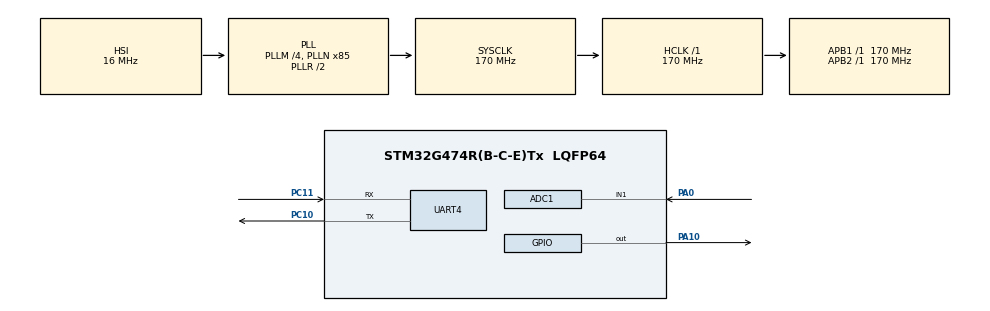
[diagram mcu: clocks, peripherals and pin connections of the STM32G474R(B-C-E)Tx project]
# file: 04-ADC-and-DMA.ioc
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ADC1.Channel-0\#ChannelRegularConversion=ADC_CHANNEL_1
ADC1.ClockPrescaler=ADC_CLOCK_ASYNC_DIV4
ADC1.ContinuousConvMode=ENABLE
ADC1.DMAContinuousRequests=ENABLE
ADC1.NbrOfConversionFlag=1
ADC1.OffsetNumber-0\#ChannelRegularConversion=ADC_OFFSET_NONE
ADC1.Rank-0\#ChannelRegularConversion=1
ADC1.SamplingTime-0\#ChannelRegularConversion=ADC_SAMPLETIME_2CYCLES_5
ADC1.master=1
Dma.ADC1.0.Direction=DMA_PERIPH_TO_MEMORY
Dma.ADC1.0.EventEnable=DISABLE
Dma.ADC1.0.Instance=DMA1_Channel1
Dma.ADC1.0.MemDataAlignment=DMA_MDATAALIGN_HALFWORD
Dma.ADC1.0.MemInc=DMA_MINC_ENABLE
Dma.ADC1.0.Mode=DMA_CIRCULAR
Dma.ADC1.0.PeriphDataAlignment=DMA_PDATAALIGN_HALFWORD
Dma.ADC1.0.PeriphInc=DMA_PINC_DISABLE
Dma.ADC1.0.Polarity=HAL_DMAMUX_REQ_GEN_RISING
Dma.ADC1.0.Priority=DMA_PRIORITY_LOW
Dma.ADC1.0.RequestNumber=1
Dma.ADC1.0.SignalID=NONE
Dma.ADC1.0.SyncEnable=DISABLE
Dma.ADC1.0.SyncPolarity=HAL_DMAMUX_SYNC_NO_EVENT
Dma.ADC1.0.SyncRequestNumber=1
Dma.ADC1.0.SyncSignalID=NONE
Dma.Request0=ADC1
Mcu.Family=STM32G4
Mcu.Name=STM32G474R(B-C-E)Tx
Mcu.Package=LQFP64
NUCLEO-G474RE.BUTTON=1
NUCLEO-G474RE.LD2=true
NUCLEO-G474RE.VCP=false
NVIC.DMA1_Channel1_IRQn=true\:0\:0\:false\:false\:true\:false\:true\:true
NVIC.EXTI15_10_IRQn=true\:0\:0\:false\:false\:true\:false\:true\:true
NVIC.PriorityGroup=NVIC_PRIORITYGROUP_4
PA0.Mode=IN1-Single-Ended
PA0.Signal=ADC1_IN1
PA10.Signal=GPIO_Output
PA13.GPIO_Label=T_SWDIO
PA13.Signal=SYS_JTMS-SWDIO
PA14.GPIO_Label=T_SWCLK
PA14.Signal=SYS_JTCK-SWCLK
PB3.GPIO_Label=T_SWO
PB3.Signal=SYS_JTDO-SWO
PC10.Mode=Asynchronous
PC10.Signal=UART4_TX
PC11.Mode=Asynchronous
PC11.Signal=UART4_RX
PC14-OSC32_IN.GPIO_Label=RCC_OSC32_IN
PC14-OSC32_IN.Signal=RCC_OSC32_IN
PC15-OSC32_OUT.GPIO_Label=RCC_OSC32_OUT
PC15-OSC32_OUT.Signal=RCC_OSC32_OUT
PF0-OSC_IN.GPIO_Label=RCC_OSC_IN
PF0-OSC_IN.Signal=RCC_OSC_IN
PF1-OSC_OUT.GPIO_Label=RCC_OSC_OUT
PF1-OSC_OUT.Signal=RCC_OSC_OUT
ProjectManager.HeapSize=0x200
ProjectManager.StackSize=0x400
ProjectManager.TargetToolchain=STM32CubeIDE
RCC.ADC12Freq_Value=170000000
RCC.ADC345Freq_Value=170000000
RCC.AHBFreq_Value=170000000
RCC.APB1Freq_Value=170000000
RCC.APB1TimFreq_Value=170000000
RCC.APB2Freq_Value=170000000
RCC.APB2TimFreq_Value=170000000
RCC.CortexFreq_Value=170000000
RCC.EXTERNAL_CLOCK_VALUE=12288000
RCC.HCLKFreq_Value=170000000
RCC.HSE_VALUE=24000000
RCC.HSI48_VALUE=48000000
RCC.HSI_VALUE=16000000
RCC.LSE_VALUE=32768
RCC.PLLM=RCC_PLLM_DIV4
RCC.PLLN=85
RCC.RTCClockSelection=RCC_RTCCLKSOURCE_LSE
RCC.SYSCLKFreq_VALUE=170000000
RCC.SYSCLKSource=RCC_SYSCLKSOURCE_PLLCLK
RCC.USBFreq_Value=170000000
RCC.VCOOutputFreq_Value=340000000
VP_NUCLEO-G474RE_VS_BSP_COMMON.Mode=COMMON
VP_SYS_VS_DBSignals.Mode=DisableDeadBatterySignals
board=NUCLEO-G474RE

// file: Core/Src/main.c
/* USER CODE BEGIN Header */
/**
  ******************************************************************************
  * @file           : main.c
  * @brief          : Main program body
  ******************************************************************************
  * @attention
  *
  * Copyright (c) 2026 STMicroelectronics.
  * All rights reserved.
  *
  * This software is licensed under terms that can be found in the LICENSE file
  * in the root directory of this software component.
  * If no LICENSE file comes with this software, it is provided AS-IS.
  *
  ******************************************************************************
  */
/* USER CODE END Header */
#include "main.h"

/* USER CODE BEGIN Includes */
#include <string.h>
#include <stdio.h>

/* USER CODE END Includes */

/* USER CODE BEGIN PD */
#define ADC_BUF_LED 4096
/* USER CODE END PD */

ADC_HandleTypeDef hadc1;
DMA_HandleTypeDef hdma_adc1;

UART_HandleTypeDef huart4;

/* USER CODE BEGIN PV */
uint16_t adc_buf[ADC_BUF_LED];
/* USER CODE END PV */

void SystemClock_Config(void);
static void MX_GPIO_Init(void);
static void MX_DMA_Init(void);
static void MX_ADC1_Init(void);
static void MX_UART4_Init(void);

int main(void)
{

  /* MCU Configuration--------------------------------------------------------*/

  /* Reset of all peripherals, Initializes the Flash interface and the Systick. */
  HAL_Init();

  /* Configure the system clock */
  SystemClock_Config();

  /* Initialize all configured peripherals */
  MX_GPIO_Init();
  MX_DMA_Init();
  MX_ADC1_Init();
  MX_UART4_Init();
  /* USER CODE BEGIN 2 */
  HAL_ADC_Start_DMA(&hadc1, (uint32_t*)adc_buf, ADC_BUF_LED);
  /* USER CODE END 2 */

  /* Initialize led */
  BSP_LED_Init(LED_GREEN);

  /* Initialize USER push-button, will be used to trigger an interrupt each time it's pressed.*/
  BSP_PB_Init(BUTTON_USER, BUTTON_MODE_EXTI);

  /* Infinite loop */
  while (1)
  {

  }
}

void SystemClock_Config(void)
{
  RCC_OscInitTypeDef RCC_OscInitStruct = {0};
  RCC_ClkInitTypeDef RCC_ClkInitStruct = {0};

  /** Configure the main internal regulator output voltage
  */
  HAL_PWREx_ControlVoltageScaling(PWR_REGULATOR_VOLTAGE_SCALE1_BOOST);

  /** Initializes the RCC Oscillators according to the specified parameters
  * in the RCC_OscInitTypeDef structure.
  */
  RCC_OscInitStruct.OscillatorType = RCC_OSCILLATORTYPE_HSI;
  RCC_OscInitStruct.HSIState = RCC_HSI_ON;
  RCC_OscInitStruct.HSICalibrationValue = RCC_HSICALIBRATION_DEFAULT;
  RCC_OscInitStruct.PLL.PLLState = RCC_PLL_ON;
  RCC_OscInitStruct.PLL.PLLSource = RCC_PLLSOURCE_HSI;
  RCC_OscInitStruct.PLL.PLLM = RCC_PLLM_DIV4;
  RCC_OscInitStruct.PLL.PLLN = 85;
  RCC_OscInitStruct.PLL.PLLP = RCC_PLLP_DIV2;
  RCC_OscInitStruct.PLL.PLLQ = RCC_PLLQ_DIV2;
  RCC_OscInitStruct.PLL.PLLR = RCC_PLLR_DIV2;
  if (HAL_RCC_OscConfig(&RCC_OscInitStruct) != HAL_OK)
  {
    Error_Handler();
  }

  /** Initializes the CPU, AHB and APB buses clocks
  */
  RCC_ClkInitStruct.ClockType = RCC_CLOCKTYPE_HCLK|RCC_CLOCKTYPE_SYSCLK
                              |RCC_CLOCKTYPE_PCLK1|RCC_CLOCKTYPE_PCLK2;
  RCC_ClkInitStruct.SYSCLKSource = RCC_SYSCLKSOURCE_PLLCLK;
  RCC_ClkInitStruct.AHBCLKDivider = RCC_SYSCLK_DIV1;
  RCC_ClkInitStruct.APB1CLKDivider = RCC_HCLK_DIV1;
  RCC_ClkInitStruct.APB2CLKDivider = RCC_HCLK_DIV1;

  if (HAL_RCC_ClockConfig(&RCC_ClkInitStruct, FLASH_LATENCY_4) != HAL_OK)
  {
    Error_Handler();
  }
}

static void MX_ADC1_Init(void)
{

  ADC_MultiModeTypeDef multimode = {0};
  ADC_ChannelConfTypeDef sConfig = {0};

  /** Common config
  */
  hadc1.Instance = ADC1;
  hadc1.Init.ClockPrescaler = ADC_CLOCK_ASYNC_DIV4;
  hadc1.Init.Resolution = ADC_RESOLUTION_12B;
  hadc1.Init.DataAlign = ADC_DATAALIGN_RIGHT;
  hadc1.Init.GainCompensation = 0;
  hadc1.Init.ScanConvMode = ADC_SCAN_DISABLE;
  hadc1.Init.EOCSelection = ADC_EOC_SINGLE_CONV;
  hadc1.Init.LowPowerAutoWait = DISABLE;
  hadc1.Init.ContinuousConvMode = ENABLE;
  hadc1.Init.NbrOfConversion = 1;
  hadc1.Init.DiscontinuousConvMode = DISABLE;
  hadc1.Init.ExternalTrigConv = ADC_SOFTWARE_START;
  hadc1.Init.ExternalTrigConvEdge = ADC_EXTERNALTRIGCONVEDGE_NONE;
  hadc1.Init.DMAContinuousRequests = ENABLE;
  hadc1.Init.Overrun = ADC_OVR_DATA_PRESERVED;
  hadc1.Init.OversamplingMode = DISABLE;
  if (HAL_ADC_Init(&hadc1) != HAL_OK)
  {
    Error_Handler();
  }

  /** Configure the ADC multi-mode
  */
  multimode.Mode = ADC_MODE_INDEPENDENT;
  if (HAL_ADCEx_MultiModeConfigChannel(&hadc1, &multimode) != HAL_OK)
  {
    Error_Handler();
  }

  /** Configure Regular Channel
  */
  sConfig.Channel = ADC_CHANNEL_1;
  sConfig.Rank = ADC_REGULAR_RANK_1;
  sConfig.SamplingTime = ADC_SAMPLETIME_2CYCLES_5;
  sConfig.SingleDiff = ADC_SINGLE_ENDED;
  sConfig.OffsetNumber = ADC_OFFSET_NONE;
  sConfig.Offset = 0;
  if (HAL_ADC_ConfigChannel(&hadc1, &sConfig) != HAL_OK)
  {
    Error_Handler();
  }

}

static void MX_UART4_Init(void)
{

  huart4.Instance = UART4;
  huart4.Init.BaudRate = 115200;
  huart4.Init.WordLength = UART_WORDLENGTH_8B;
  huart4.Init.StopBits = UART_STOPBITS_1;
  huart4.Init.Parity = UART_PARITY_NONE;
  huart4.Init.Mode = UART_MODE_TX_RX;
  huart4.Init.HwFlowCtl = UART_HWCONTROL_NONE;
  huart4.Init.OverSampling = UART_OVERSAMPLING_16;
  huart4.Init.OneBitSampling = UART_ONE_BIT_SAMPLE_DISABLE;
  huart4.Init.ClockPrescaler = UART_PRESCALER_DIV1;
  huart4.AdvancedInit.AdvFeatureInit = UART_ADVFEATURE_NO_INIT;
  if (HAL_UART_Init(&huart4) != HAL_OK)
  {
    Error_Handler();
  }
  if (HAL_UARTEx_SetTxFifoThreshold(&huart4, UART_TXFIFO_THRESHOLD_1_8) != HAL_OK)
  {
    Error_Handler();
  }
  if (HAL_UARTEx_SetRxFifoThreshold(&huart4, UART_RXFIFO_THRESHOLD_1_8) != HAL_OK)
  {
    Error_Handler();
  }
  if (HAL_UARTEx_DisableFifoMode(&huart4) != HAL_OK)
  {
    Error_Handler();
  }

}

static void MX_DMA_Init(void)
{

  /* DMA controller clock enable */
  __HAL_RCC_DMAMUX1_CLK_ENABLE();
  __HAL_RCC_DMA1_CLK_ENABLE();

  /* DMA interrupt init */
  /* DMA1_Channel1_IRQn interrupt configuration */
  HAL_NVIC_SetPriority(DMA1_Channel1_IRQn, 0, 0);
  HAL_NVIC_EnableIRQ(DMA1_Channel1_IRQn);

}

static void MX_GPIO_Init(void)
{
  GPIO_InitTypeDef GPIO_InitStruct = {0};

  /* GPIO Ports Clock Enable */
  __HAL_RCC_GPIOC_CLK_ENABLE();
  __HAL_RCC_GPIOF_CLK_ENABLE();
  __HAL_RCC_GPIOA_CLK_ENABLE();
  __HAL_RCC_GPIOB_CLK_ENABLE();

  /*Configure GPIO pin Output Level */
  HAL_GPIO_WritePin(GPIOA, GPIO_PIN_10, GPIO_PIN_RESET);

  /*Configure GPIO pin : PA10 */
  GPIO_InitStruct.Pin = GPIO_PIN_10;
  GPIO_InitStruct.Mode = GPIO_MODE_OUTPUT_PP;
  GPIO_InitStruct.Pull = GPIO_NOPULL;
  GPIO_InitStruct.Speed = GPIO_SPEED_FREQ_LOW;
  HAL_GPIO_Init(GPIOA, &GPIO_InitStruct);

}

/* USER CODE BEGIN 4 */

// Called when first half of buffer is filled
void HAL_ADC_ConvHalfCpltCallback(ADC_HandleTypeDef* hadc) {
	HAL_GPIO_WritePin(GPIOA, GPIO_PIN_5, GPIO_PIN_SET);
}

void HAL_ADC_ConvCpltCallback(ADC_HandleTypeDef* hadc) {
	HAL_GPIO_WritePin(GPIOA, GPIO_PIN_5, GPIO_PIN_RESET);
}

/* USER CODE END 4 */

void Error_Handler(void)
{
  __disable_irq();
  while (1)
  {
  }
}
